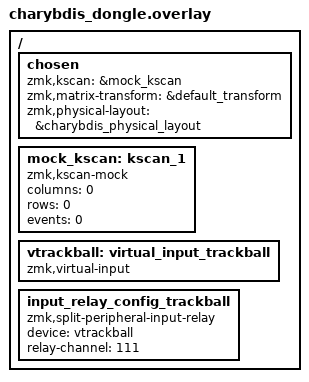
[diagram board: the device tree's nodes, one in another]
#include "charybdis.dtsi"
#include "charybdis-layouts.dtsi"

/ {
    chosen {
        zmk,kscan = &mock_kscan;
        zmk,matrix-transform = &default_transform;
        zmk,physical-layout = &charybdis_physical_layout;
    };

    mock_kscan: kscan_1 {
        compatible = "zmk,kscan-mock";
        columns = <0>;
        rows = <0>;
        events = <0>;
    };

    vtrackball: virtual_input_trackball {
        compatible = "zmk,virtual-input";
    };

    input_relay_config_trackball {
        compatible = "zmk,split-peripheral-input-relay";
        device = <&vtrackball>;
        relay-channel = <111>;
    };
};
